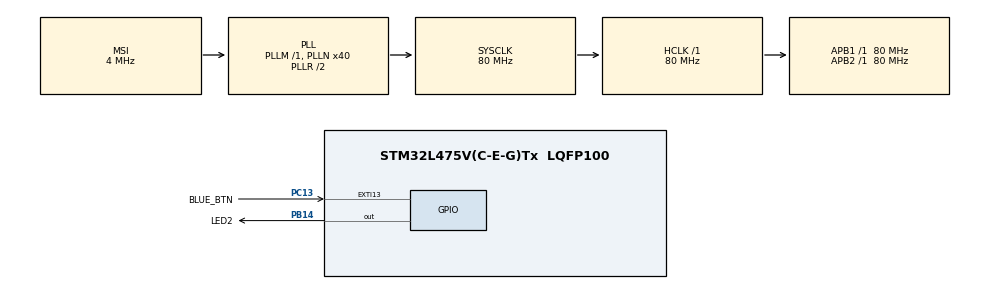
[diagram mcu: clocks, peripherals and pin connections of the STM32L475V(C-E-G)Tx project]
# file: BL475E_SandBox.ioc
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FREERTOS.Tasks01=defaultTask,24,128,StartDefaultTask,Default,NULL,Dynamic,NULL,NULL
FREERTOS.configUSE_NEWLIB_REENTRANT=1
Mcu.Family=STM32L4
Mcu.Name=STM32L475V(C-E-G)Tx
Mcu.Package=LQFP100
NVIC.EXTI15_10_IRQn=true\:5\:0\:false\:false\:true\:true\:true\:true\:true
NVIC.PriorityGroup=NVIC_PRIORITYGROUP_4
NVIC.TIM6_DAC_IRQn=true\:15\:0\:false\:false\:true\:false\:false\:true\:true
NVIC.TimeBase=TIM6_DAC_IRQn
NVIC.TimeBaseIP=TIM6
PA13\ (JTMS-SWDIO).Mode=Serial_Wire
PA13\ (JTMS-SWDIO).Signal=SYS_JTMS-SWDIO
PA14\ (JTCK-SWCLK).Mode=Serial_Wire
PA14\ (JTCK-SWCLK).Signal=SYS_JTCK-SWCLK
PB14.GPIO_Label=LED2
PB14.Signal=GPIO_Output
PC13.GPIO_Label=BLUE_BTN
PC13.GPIO_ModeDefaultEXTI=GPIO_MODE_IT_FALLING
PC13.GPIO_PuPd=GPIO_PULLUP
PC13.Signal=GPXTI13
ProjectManager.HeapSize=0x1000
ProjectManager.StackSize=0x800
ProjectManager.TargetToolchain=STM32CubeIDE
RCC.ADCFreq_Value=48000000
RCC.AHBFreq_Value=80000000
RCC.APB1Freq_Value=80000000
RCC.APB1TimFreq_Value=80000000
RCC.APB2Freq_Value=80000000
RCC.APB2TimFreq_Value=80000000
RCC.CortexFreq_Value=80000000
RCC.HCLKFreq_Value=80000000
RCC.HSE_VALUE=8000000
RCC.HSI_VALUE=16000000
RCC.LSE_VALUE=32768
RCC.MSI_VALUE=4000000
RCC.PLLN=40
RCC.PLLSAI1N=24
RCC.SYSCLKFreq_VALUE=80000000
RCC.SYSCLKSource=RCC_SYSCLKSOURCE_PLLCLK
RCC.USBFreq_Value=48000000
RCC.VCOOutputFreq_Value=160000000
VP_FREERTOS_VS_CMSIS_V2.Mode=CMSIS_V2
VP_SYS_VS_tim6.Mode=TIM6
board=B-L475E-IOT01A1

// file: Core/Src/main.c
/* USER CODE BEGIN Header */
/**
  ******************************************************************************
  * @file           : main.c
  * @brief          : Main program body
  ******************************************************************************
  * @attention
  *
  * Copyright (c) 2025 STMicroelectronics.
  * All rights reserved.
  *
  * This software is licensed under terms that can be found in the LICENSE file
  * in the root directory of this software component.
  * If no LICENSE file comes with this software, it is provided AS-IS.
  *
  ******************************************************************************
  */
/* USER CODE END Header */
#include "main.h"
#include "cmsis_os.h"

/* USER CODE BEGIN Includes */
#include "user_task.h"
/* USER CODE END Includes */

/* Definitions for defaultTask */
osThreadId_t defaultTaskHandle;
const osThreadAttr_t defaultTask_attributes = {
  .name = "defaultTask",
  .stack_size = 128 * 4,
  .priority = (osPriority_t) osPriorityNormal,
};
/* USER CODE BEGIN PV */
osMessageQueueId_t buttonQueueHandle;
/* USER CODE END PV */

void SystemClock_Config(void);
static void MX_GPIO_Init(void);
void StartDefaultTask(void *argument);

int main(void)
{

  /* MCU Configuration--------------------------------------------------------*/

  /* Reset of all peripherals, Initializes the Flash interface and the Systick. */
  HAL_Init();

  /* Configure the system clock */
  SystemClock_Config();

  /* Initialize all configured peripherals */
  MX_GPIO_Init();

  /* Init scheduler */
  osKernelInitialize();

  /* Create the thread(s) */
  /* creation of defaultTask */
  defaultTaskHandle = osThreadNew(StartDefaultTask, NULL, &defaultTask_attributes);

  /* USER CODE BEGIN RTOS_THREADS */
  /* add threads, ... */

  buttonQueueHandle = osMessageQueueNew(4, sizeof(uint8_t), NULL);

  const osThreadAttr_t ledTask_attributes = {
    .name = "ledTask",
    .priority = osPriorityNormal,
    .stack_size = 128 * 4
  };
  osThreadNew(LedTask, NULL, &ledTask_attributes);
  /* USER CODE END RTOS_THREADS */

  /* Start scheduler */
  osKernelStart();

  /* We should never get here as control is now taken by the scheduler */

  /* Infinite loop */
  while (1)
  {

  }
}

void SystemClock_Config(void)
{
  RCC_OscInitTypeDef RCC_OscInitStruct = {0};
  RCC_ClkInitTypeDef RCC_ClkInitStruct = {0};

  /** Configure the main internal regulator output voltage
  */
  if (HAL_PWREx_ControlVoltageScaling(PWR_REGULATOR_VOLTAGE_SCALE1) != HAL_OK)
  {
    Error_Handler();
  }

  /** Initializes the RCC Oscillators according to the specified parameters
  * in the RCC_OscInitTypeDef structure.
  */
  RCC_OscInitStruct.OscillatorType = RCC_OSCILLATORTYPE_MSI;
  RCC_OscInitStruct.MSIState = RCC_MSI_ON;
  RCC_OscInitStruct.MSICalibrationValue = 0;
  RCC_OscInitStruct.MSIClockRange = RCC_MSIRANGE_6;
  RCC_OscInitStruct.PLL.PLLState = RCC_PLL_ON;
  RCC_OscInitStruct.PLL.PLLSource = RCC_PLLSOURCE_MSI;
  RCC_OscInitStruct.PLL.PLLM = 1;
  RCC_OscInitStruct.PLL.PLLN = 40;
  RCC_OscInitStruct.PLL.PLLP = RCC_PLLP_DIV7;
  RCC_OscInitStruct.PLL.PLLQ = RCC_PLLQ_DIV2;
  RCC_OscInitStruct.PLL.PLLR = RCC_PLLR_DIV2;
  if (HAL_RCC_OscConfig(&RCC_OscInitStruct) != HAL_OK)
  {
    Error_Handler();
  }

  /** Initializes the CPU, AHB and APB buses clocks
  */
  RCC_ClkInitStruct.ClockType = RCC_CLOCKTYPE_HCLK|RCC_CLOCKTYPE_SYSCLK
                              |RCC_CLOCKTYPE_PCLK1|RCC_CLOCKTYPE_PCLK2;
  RCC_ClkInitStruct.SYSCLKSource = RCC_SYSCLKSOURCE_PLLCLK;
  RCC_ClkInitStruct.AHBCLKDivider = RCC_SYSCLK_DIV1;
  RCC_ClkInitStruct.APB1CLKDivider = RCC_HCLK_DIV1;
  RCC_ClkInitStruct.APB2CLKDivider = RCC_HCLK_DIV1;

  if (HAL_RCC_ClockConfig(&RCC_ClkInitStruct, FLASH_LATENCY_4) != HAL_OK)
  {
    Error_Handler();
  }
}

static void MX_GPIO_Init(void)
{
  GPIO_InitTypeDef GPIO_InitStruct = {0};

  /* GPIO Ports Clock Enable */
  __HAL_RCC_GPIOC_CLK_ENABLE();
  __HAL_RCC_GPIOB_CLK_ENABLE();
  __HAL_RCC_GPIOA_CLK_ENABLE();

  /*Configure GPIO pin Output Level */
  HAL_GPIO_WritePin(LED2_GPIO_Port, LED2_Pin, GPIO_PIN_RESET);

  /*Configure GPIO pin : BLUE_BTN_Pin */
  GPIO_InitStruct.Pin = BLUE_BTN_Pin;
  GPIO_InitStruct.Mode = GPIO_MODE_IT_FALLING;
  GPIO_InitStruct.Pull = GPIO_PULLUP;
  HAL_GPIO_Init(BLUE_BTN_GPIO_Port, &GPIO_InitStruct);

  /*Configure GPIO pin : LED2_Pin */
  GPIO_InitStruct.Pin = LED2_Pin;
  GPIO_InitStruct.Mode = GPIO_MODE_OUTPUT_PP;
  GPIO_InitStruct.Pull = GPIO_NOPULL;
  GPIO_InitStruct.Speed = GPIO_SPEED_FREQ_LOW;
  HAL_GPIO_Init(LED2_GPIO_Port, &GPIO_InitStruct);

  /* EXTI interrupt init*/
  HAL_NVIC_SetPriority(EXTI15_10_IRQn, 5, 0);
  HAL_NVIC_EnableIRQ(EXTI15_10_IRQn);

}

/* USER CODE BEGIN 4 */
void HAL_GPIO_EXTI_Callback(uint16_t GPIO_Pin)
{
  if (GPIO_Pin == GPIO_PIN_13)
  {
    if (buttonQueueHandle != NULL) {
      uint8_t signal = 1;
      osMessageQueuePut(buttonQueueHandle, &signal, 0, 0);
    }
  }
}
/* USER CODE END 4 */

void StartDefaultTask(void *argument)
{
  for(;;)
  {
    osDelay(1);
  }
}

void HAL_TIM_PeriodElapsedCallback(TIM_HandleTypeDef *htim)
{
  if (htim->Instance == TIM6)
  {
    HAL_IncTick();
  }
}

void Error_Handler(void)
{
  __disable_irq();
  while (1)
  {
  }
}
